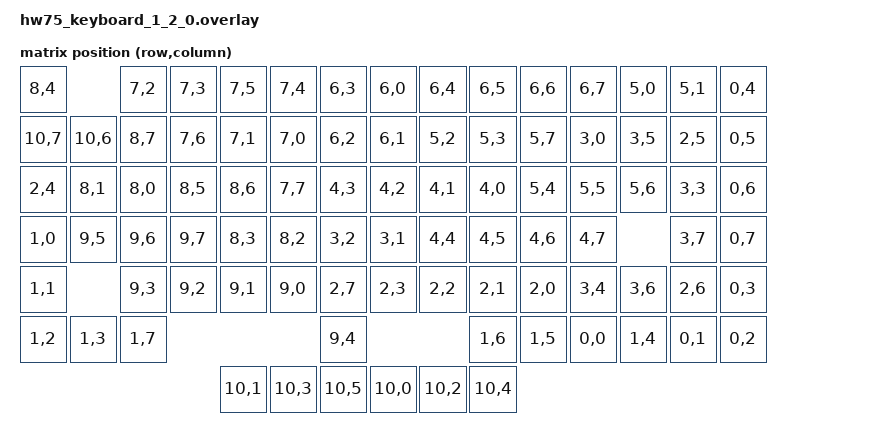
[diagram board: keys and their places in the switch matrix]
/*
 * Copyright (c) 2022-2023 XiNGRZ
 * SPDX-License-Identifier: MIT
 */

#include <dt-bindings/zmk/matrix_transform.h>

&default_transform {
    map = <
        RC(8, 4)          RC(7, 2) RC(7, 3) RC(7, 5) RC(7, 4) RC(6, 3) RC(6, 0) RC(6, 4) RC(6, 5) RC(6, 6) RC(6, 7) RC(5, 0) RC(5, 1) RC(0, 4)
        RC(10,7) RC(10,6) RC(8, 7) RC(7, 6) RC(7, 1) RC(7, 0) RC(6, 2) RC(6, 1) RC(5, 2) RC(5, 3) RC(5, 7) RC(3, 0) RC(3, 5) RC(2, 5) RC(0, 5)
        RC(2, 4) RC(8, 1) RC(8, 0) RC(8, 5) RC(8, 6) RC(7, 7) RC(4, 3) RC(4, 2) RC(4, 1) RC(4, 0) RC(5, 4) RC(5, 5) RC(5, 6) RC(3, 3) RC(0, 6)
        RC(1, 0) RC(9, 5) RC(9, 6) RC(9, 7) RC(8, 3) RC(8, 2) RC(3, 2) RC(3, 1) RC(4, 4) RC(4, 5) RC(4, 6) RC(4, 7)          RC(3, 7) RC(0, 7)
        RC(1, 1)          RC(9, 3) RC(9, 2) RC(9, 1) RC(9, 0) RC(2, 7) RC(2, 3) RC(2, 2) RC(2, 1) RC(2, 0) RC(3, 4) RC(3, 6) RC(2, 6) RC(0, 3)
        RC(1, 2) RC(1, 3) RC(1, 7)                            RC(9, 4)                   RC(1, 6) RC(1, 5) RC(0, 0) RC(1, 4) RC(0, 1) RC(0, 2)
                                            RC(10,1) RC(10,3) RC(10,5) RC(10,0) RC(10,2) RC(10,4)
    >;
};

&led_strip {
	chain-length = <103>;
	map = <
		/* hub */
		 100 99  98  97  96  95  94  93  92  91  90  89  88  87  86  85 102 101
		/* keys */
		 13      12  11  10   9   8   7   6   5   4   3   2   1   0
		 14  15  16  17  18  19  20  21  22  23  24  25  26  27  28
		 43  42  41  40  39  38  37  36  35  34  33  32  31  30  29
		 44  45  46  47  48  49  50  51  52  53  54  55      56  57
		 71      70  69  68  67  66  65  64  63  62  61  60  59  58
		 72  73  74              75          76  77  78  79  80  81
		/* status (top/mid/bottom) */
		 84  83  82
	>;
};

&ws2812 {
	chain-length = <103>;
};
